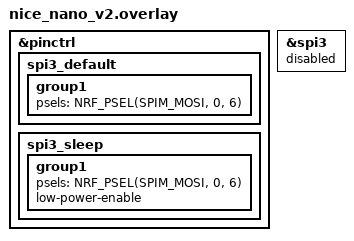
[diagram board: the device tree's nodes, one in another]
#include <dt-bindings/led/led.h>

&pinctrl {
    spi3_default: spi3_default {
        group1 {
            psels = <NRF_PSEL(SPIM_MOSI, 0, 6)>;
        };
    };

    spi3_sleep: spi3_sleep {
        group1 {
            psels = <NRF_PSEL(SPIM_MOSI, 0, 6)>;
            low-power-enable;
        };
    };
};

/* No underglow LEDs on Will's Temper — leave SPI/WS2812 off */
&spi3 {
    status = "disabled";
};
